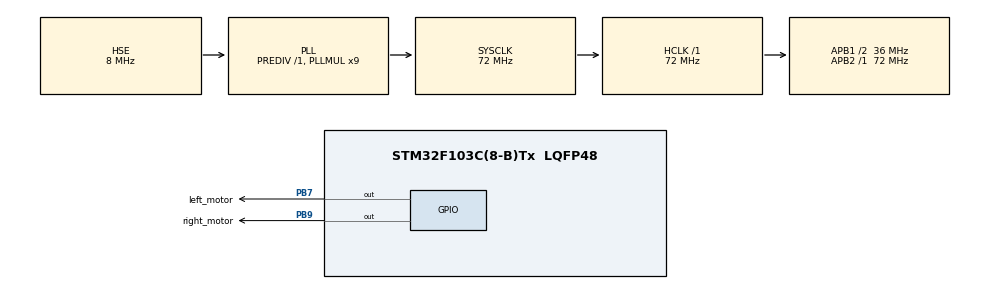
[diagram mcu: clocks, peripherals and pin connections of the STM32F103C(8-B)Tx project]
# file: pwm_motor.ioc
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Mcu.Family=STM32F1
Mcu.Name=STM32F103C(8-B)Tx
Mcu.Package=LQFP48
NVIC.PriorityGroup=NVIC_PRIORITYGROUP_4
NVIC.TIM4_IRQn=true\:0\:0\:false\:false\:true\:true\:true\:true
PA13.Mode=Serial_Wire
PA13.Signal=SYS_JTMS-SWDIO
PA14.Mode=Serial_Wire
PA14.Signal=SYS_JTCK-SWCLK
PB6.GPIO_Speed=GPIO_SPEED_FREQ_HIGH
PB6.Signal=S_TIM4_CH1
PB7.GPIO_Label=left_motor
PB7.Signal=GPIO_Output
PB8.GPIO_Speed=GPIO_SPEED_FREQ_HIGH
PB8.Signal=S_TIM4_CH3
PB9.GPIO_Label=right_motor
PB9.Signal=GPIO_Output
PC14-OSC32_IN.Mode=LSE-External-Oscillator
PC14-OSC32_IN.Signal=RCC_OSC32_IN
PC15-OSC32_OUT.Mode=LSE-External-Oscillator
PC15-OSC32_OUT.Signal=RCC_OSC32_OUT
PD0-OSC_IN.Mode=HSE-External-Oscillator
PD0-OSC_IN.Signal=RCC_OSC_IN
PD1-OSC_OUT.Mode=HSE-External-Oscillator
PD1-OSC_OUT.Signal=RCC_OSC_OUT
ProjectManager.HeapSize=0x200
ProjectManager.StackSize=0x400
ProjectManager.TargetToolchain=MDK-ARM V5.32
RCC.AHBFreq_Value=72000000
RCC.APB1CLKDivider=RCC_HCLK_DIV2
RCC.APB1Freq_Value=36000000
RCC.APB1TimFreq_Value=72000000
RCC.APB2Freq_Value=72000000
RCC.APB2TimFreq_Value=72000000
RCC.HCLKFreq_Value=72000000
RCC.PLLMUL=RCC_PLL_MUL9
RCC.PLLSourceVirtual=RCC_PLLSOURCE_HSE
RCC.SYSCLKFreq_VALUE=72000000
RCC.SYSCLKSource=RCC_SYSCLKSOURCE_PLLCLK
RCC.USBFreq_Value=72000000
SH.S_TIM4_CH1.0=TIM4_CH1
SH.S_TIM4_CH3.0=TIM4_CH3
TIM4.Channel-PWM\ Generation2\ No\ Output=TIM_CHANNEL_2
TIM4.Channel-PWM\ Generation4\ No\ Output=TIM_CHANNEL_4
VP_TIM4_VS_ClockSourceINT.Mode=Internal
VP_TIM4_VS_no_output2.Mode=PWM Generation2 No Output
VP_TIM4_VS_no_output4.Mode=PWM Generation4 No Output
board=custom

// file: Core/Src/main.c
/* USER CODE BEGIN Header */
/**
  ******************************************************************************
  * @file           : main.c
  * @brief          : Main program body
  ******************************************************************************
  * @attention
  *
  * Copyright (c) 2025 STMicroelectronics.
  * All rights reserved.
  *
  * This software is licensed under terms that can be found in the LICENSE file
  * in the root directory of this software component.
  * If no LICENSE file comes with this software, it is provided AS-IS.
  *
  ******************************************************************************
  */
/* USER CODE END Header */
#include "main.h"
#include "tim.h"
#include "gpio.h"

/* USER CODE BEGIN Includes */
#include <stdio.h>
/* USER CODE END Includes */

/* USER CODE BEGIN PM */
//通用接口，主频80MHz，预分频值为80-1，设置PWM的脉冲频率freq(0.16-10kHz)、占空比参数 pulse (0-100)
void set_pwm_param(TIM_HandleTypeDef htim, uint32_t Channel, uint32_t freq, uint16_t duty)
{
    uint16_t prescaler = 72-1;
    uint64_t tim_clk_freq = 72000000;
    //计算PWM频率，所对应的自动重装载值   ---> ARR = 主频 / (预分频+1) / 预期PWM频率(Hz) - 1
    float pwm_freq_arr  = (tim_clk_freq * 1.0) / (prescaler+1) / freq * 1.0 - 1;
    //计算PWM占空比，所对应比较寄存器的值 ---> CCR = 预期占空比 * (自动重装载值+1)
    //占空比则由捕获/比较寄存器（TIMx_CRx）寄存器决定。占空比:duty = Pluse / (ARR+1)
    float pwm_duty_pulse = duty * 1.0 / 100 * (pwm_freq_arr + 1);

    //配置PSC预分频值
    __HAL_TIM_SET_PRESCALER(&htim, prescaler);
    //配置PWM频率 ARR
    __HAL_TIM_SetAutoreload(&htim, (uint16_t)pwm_freq_arr);
    //配置PWM占空比
    __HAL_TIM_SetCompare(&htim, Channel, (uint16_t)pwm_duty_pulse);
    printf("pwm_freq_arr:%.2f\r\n", pwm_freq_arr);
    printf("pwm_duty_pulse:%.2f\r\n", pwm_duty_pulse);
}
/* USER CODE END PM */

void SystemClock_Config(void);

int main(void)
{

  /* MCU Configuration--------------------------------------------------------*/

  /* Reset of all peripherals, Initializes the Flash interface and the Systick. */
  HAL_Init();

  /* Configure the system clock */
  SystemClock_Config();

  /* Initialize all configured peripherals */
  MX_GPIO_Init();
  MX_TIM4_Init();

  /* Infinite loop */
  /* USER CODE BEGIN WHILE */
  while (1)
  {
		set_pwm_param(htim4,TIM_CHANNEL_2, 10000, 50);
    /* USER CODE END WHILE */

  }
}

void SystemClock_Config(void)
{
  RCC_OscInitTypeDef RCC_OscInitStruct = {0};
  RCC_ClkInitTypeDef RCC_ClkInitStruct = {0};

  /** Initializes the RCC Oscillators according to the specified parameters
  * in the RCC_OscInitTypeDef structure.
  */
  RCC_OscInitStruct.OscillatorType = RCC_OSCILLATORTYPE_HSE;
  RCC_OscInitStruct.HSEState = RCC_HSE_ON;
  RCC_OscInitStruct.HSEPredivValue = RCC_HSE_PREDIV_DIV1;
  RCC_OscInitStruct.HSIState = RCC_HSI_ON;
  RCC_OscInitStruct.PLL.PLLState = RCC_PLL_ON;
  RCC_OscInitStruct.PLL.PLLSource = RCC_PLLSOURCE_HSE;
  RCC_OscInitStruct.PLL.PLLMUL = RCC_PLL_MUL9;
  if (HAL_RCC_OscConfig(&RCC_OscInitStruct) != HAL_OK)
  {
    Error_Handler();
  }

  /** Initializes the CPU, AHB and APB buses clocks
  */
  RCC_ClkInitStruct.ClockType = RCC_CLOCKTYPE_HCLK|RCC_CLOCKTYPE_SYSCLK
                              |RCC_CLOCKTYPE_PCLK1|RCC_CLOCKTYPE_PCLK2;
  RCC_ClkInitStruct.SYSCLKSource = RCC_SYSCLKSOURCE_PLLCLK;
  RCC_ClkInitStruct.AHBCLKDivider = RCC_SYSCLK_DIV1;
  RCC_ClkInitStruct.APB1CLKDivider = RCC_HCLK_DIV2;
  RCC_ClkInitStruct.APB2CLKDivider = RCC_HCLK_DIV1;

  if (HAL_RCC_ClockConfig(&RCC_ClkInitStruct, FLASH_LATENCY_2) != HAL_OK)
  {
    Error_Handler();
  }
}

void Error_Handler(void)
{
  __disable_irq();
  while (1)
  {
  }
}
